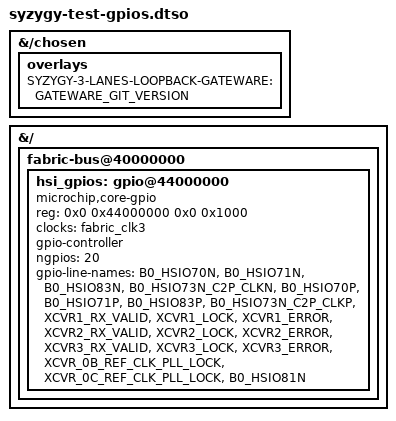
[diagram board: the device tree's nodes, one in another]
// SPDX-License-Identifier: (GPL-2.0 OR MIT)
/* Copyright (c) 2020-2021 Microchip Technology Inc */

/dts-v1/;
/plugin/;

&{/chosen} {
	overlays {
		SYZYGY-3-LANES-LOOPBACK-GATEWARE = "GATEWARE_GIT_VERSION";
	};
};

&{/} {
	fabric-bus@40000000 {
		hsi_gpios: gpio@44000000 {
			compatible = "microchip,core-gpio";
			reg = <0x0 0x44000000 0x0 0x1000>;
			clocks = <&fabric_clk3>;
			gpio-controller;
			#gpio-cells = <2>;
			ngpios=<20>;
			status = "okay";
			gpio-line-names = "B0_HSIO70N", "B0_HSIO71N", "B0_HSIO83N", "B0_HSIO73N_C2P_CLKN",
			                  "B0_HSIO70P", "B0_HSIO71P", "B0_HSIO83P", "B0_HSIO73N_C2P_CLKP",
			                  "XCVR1_RX_VALID", "XCVR1_LOCK", "XCVR1_ERROR",
							  "XCVR2_RX_VALID", "XCVR2_LOCK", "XCVR2_ERROR",
							  "XCVR3_RX_VALID", "XCVR3_LOCK", "XCVR3_ERROR", 
							  "XCVR_0B_REF_CLK_PLL_LOCK", "XCVR_0C_REF_CLK_PLL_LOCK", "B0_HSIO81N";
		};
	};
};
